# GD32A72_A74x register map
File version: 1.0
CPU: CM7 r2p1, little endian, MPU, FPU, DSP, 4 interrupt priority bits
Registers are 32-bit, read-write, reset 0x0 unless marked. A register's access mark holds for its fields unless they carry their own. Offsets are from the block's base; [hi:lo] are bit positions; {n}, {i} and the like mark numbered series; 'fields as' and 'values as' point back to an identical list.

## IRM — Interrupt requests management
Base 0x40023800
0x00 CTL — Control register
  [0] MOEN — Monitor enable
0x04 IRN wo reset 0xFF — Interrupt response number register
  [7:0] IRQN — The number for interrupt response from the interrupt service routine
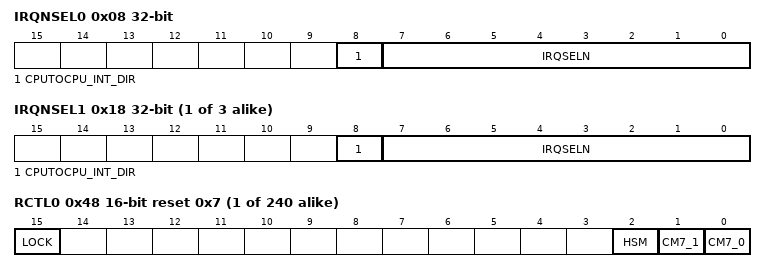
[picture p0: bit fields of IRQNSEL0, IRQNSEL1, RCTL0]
0x08 IRQNSEL0 — Interrupt request number select register 0
  [8] CPUTOCPU_INT_DIR — The selected IRQ21~IRQ24 interrupt direction to monitor
  [7:0] IRQSELN — The selected interrupt request number to monitor
0x0C CKTH0 — Clock threshold register 0
  [23:0] MCT — The maximum clock threshold from request to interrupt response for the selected monitored interrupt
0x10 CKCNT0 — Clock counter register 0
  [23:0] CLKCNT — IRM clock cycle counter
0x14 CMPO0 ro — Comparison output register
  [0] CMPOR — Comparison between the set interrupt response threshold of IRM_CKTH and the counter value of IRM_CKCNT
{0x8+0x10*i} IRQNSEL{i} (i=1..3) — Interrupt request number select register {i}
  [8] CPUTOCPU_INT_DIR — The selected IRQ21~IRQ24 interrupt direction to monitor
  [7:0] IRQSELN — the selected interrupt request number to monitor
0x1C CKTH1 — Clock threshold register
  [23:0] MCT — the maximum clock threshold from request to interrupt response for the selected monitored interrupt
{0x10+0x10*i} CKCNT{i} (i=1..3) — Clock counter register
  [23:0] CLKCNT — irm clock cycle counter
{0x14+0x10*i} CMPO{i} ro (i=1..3) — Comparison output register {i}
  fields as CMPO0
0x2C CKTH2 — Clock threshold register 2
  fields as CKTH1
0x3C CKTH3 — Clock threshold register
  fields as CKTH1
{0x48+2i} RCTL{i} 16-bit reset 0x7 (i=0..239) — Routing control register {i}
  [15] LOCK — Lock the routing of the corresponding interrupt request
  [2] HSM — HSM Cortex-M23 core Interrupt routing enable
  [1] CM7_1 — Cortex-M7_1 core interrupt routing enable
  [0] CM7_0 — Cortex-M7_0 core interrupt routing enable

## JDC — Debug system JDC
Base 0x4000EC00
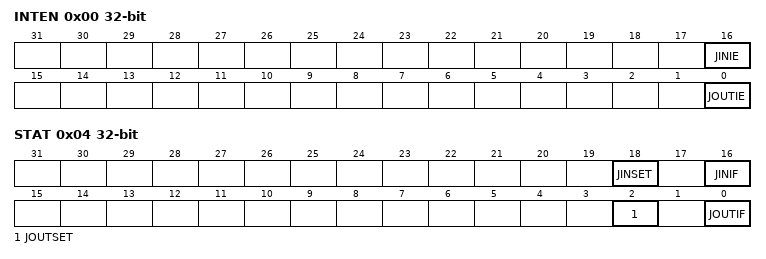
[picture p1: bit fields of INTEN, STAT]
0x00 INTEN — Interrupt enable register
  [16] JINIE — JIN interrupt enable
  [0] JOUTIE — JOUT interrupt enable
0x04 STAT access per field — Status register
  [18] JINSET ro
  [16] JINIF rw — The new data is written to the JDC_JIN_APB_DATA register interrupt flag
  [2] JOUTSET ro
  [0] JOUTIF rw — The JOUTSET bit is cleared by tool reading JDC_JOUT_DATA register interrupt flag
0x08 JOUT_APB_DATA
  [31:0] JOUT_APB_DATA — The JDC_JOUT_APB_DATA register stores data that has been written via APB
0x0C JIN_APB_DATA ro
  [31:0] JIN_APB_DATA — The JDC_JIN_APB_DATA register contains data written to the JTAG input data register (JDC_JIN_DATA) through the JTAG port

## MCMUA — Multi-core messaging unit
Base 0x49008000
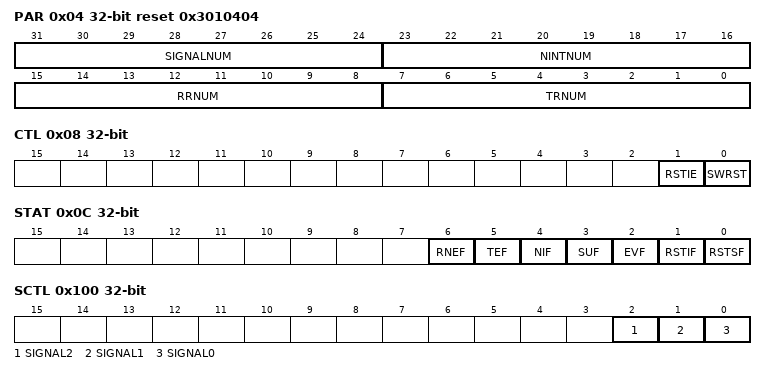
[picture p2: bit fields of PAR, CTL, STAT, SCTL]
0x04 PAR ro reset 0x3010404 — Parameter register
  [31:24] SIGNALNUM — The number of signal bits in the MCMUA_SCTL register and MCMUA_SSTAT register
  [23:16] NINTNUM — The number of normal interrupt requests available
  [15:8] RRNUM — The number of receive registers
  [7:0] TRNUM — The number of transmit registers
0x08 CTL wo — Control register
  [1] RSTIE — mcmua reset interrupt enable (only can be reset by system reset)
  [0] SWRST — Software reset MCMU (always read 0)
0x0C STAT access per field — Status register
  [6] RNEF ro — Receive not empty flag
  [5] TEF ro — Transmit empty flag
  [4] NIF ro — Normal interrupt flag
  [3] SUF ro — Signal update flag
  [2] EVF ro — MCMUA side event flag
  [1] RSTIF rw — MCMU reset interrupt flag
  [0] RSTSF ro — MCMU reset state flag
0x100 SCTL — Signal control register
  [2] SIGNAL2 — MCMUA to MCMUB signal2
  [1] SIGNAL1 — MCMUA to MCMUB signal1
  [0] SIGNAL0 — MCMUA to MCMUB signal0
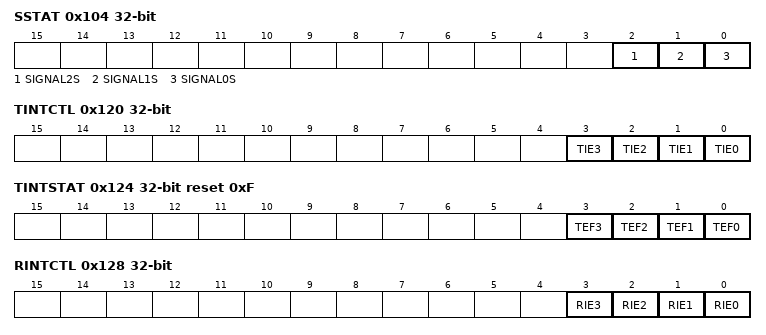
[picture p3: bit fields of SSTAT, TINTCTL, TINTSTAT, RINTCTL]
0x104 SSTAT ro — Signal status register
  [2] SIGNAL2S — MCMUB to MCMUA signal2 status
  [1] SIGNAL1S — MCMUB to MCMUA signal1 status
  [0] SIGNAL0S — MCMUB to MCMUA signal0 status
0x110 NINTEN — Normal interrupt enable register
  [0] NIE0 — Enable normal interrupt
0x114 NINTCTL — Normal interrupt control register
  [0] NIR0 — MCMUA normal interrupt request (only be cleared by MCMUB)
0x118 NINTSTAT — Normal interrupt Status register
  [0] NIF0 — MCMUA normal interrupt flag from MCMUB
0x120 TINTCTL — Transmit Interrupt Control register
  [n] TIE{n} (n=0..3) — MCMUA transmit interrupt {n} enable
0x124 TINTSTAT ro reset 0xF — Transmit Interrupt Status register
  [n] TEF{n} (n=0..3) — MCMUA transmit register {n} empty
0x128 RINTCTL — Receive Interrupt Control register
  [n] RIE{n} (n=0..3) — mcmua receive interrupt enable {n}
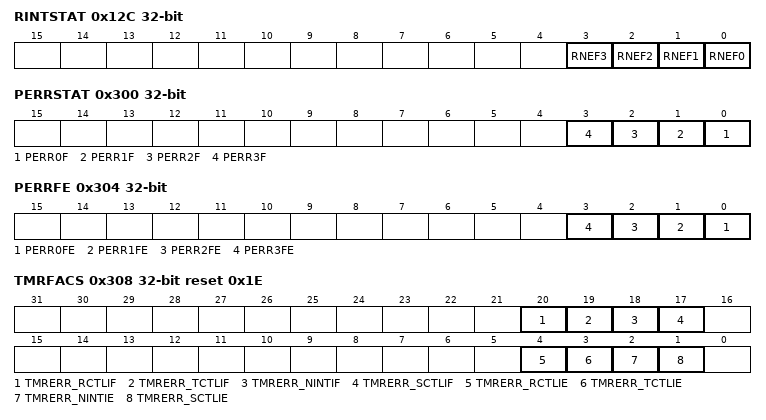
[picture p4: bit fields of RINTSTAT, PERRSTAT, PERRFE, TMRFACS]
0x12C RINTSTAT ro — Receive Interrupt Status register
  [n] RNEF{n} (n=0..3) — mcmua_rdatax register {n} is not empty
{0x200+4i} TDATA{i} wo (i=0..3) — Transmit data register {i}
  [31:0] TDATA — MCMUA Transmit Data
{0x280+4i} RDATA{i} ro (i=0..3) — Receive data register {i}
  [31:0] RDATA — MCMUA Receive Data
0x300 PERRSTAT — Parity Error Status register
  [n] PERR{n}F (n=0..3) — Transmit / receive register {n} parity check error flag
0x304 PERRFE — Parity Error fault enable register
  [n] PERR{n}FE (n=0..3) — Enable transmit /receive register {n} parity check error connection to FMU
0x308 TMRFACS reset 0x1E — TMR fault control and status register
  [20] TMRERR_RCTLIF — tmr fault flag of the receive interrupt enable bits in the receive control register in mcmua side
  [19] TMRERR_TCTLIF — tmr fault flag of the transmit interrupt enable in the transmit control register in mcmua side
  [18] TMRERR_NINTIF — tmr fault flag of the normal interrupt enable and request in the normal interrupt enable and control registers in mcmua side
  [17] TMRERR_SCTLIF — tmr fault flag of the signal control register in mcmua side
  [4] TMRERR_RCTLIE — enable tmr fault alarm interrupt of the receive data interrupt enable in mcmua_rintctl
  [3] TMRERR_TCTLIE — Enable TMR fault alarm interrupt of the transmit interrupt enable in MCMUB_TINTCTL
  [2] TMRERR_NINTIE — enable tmr fault alarm interrupt of the normal interrupt enable and request in mcmua_ninten and mcmua_nintctl
  [1] TMRERR_SCTLIE — enable tmr fault alarm interrupt in mcmub_sctl
